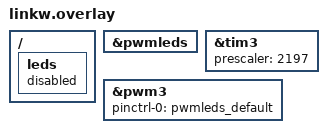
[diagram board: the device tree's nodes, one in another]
/*
 * Copyright (c) 2025 Michael Hope <michaelh@juju.nz>
 *
 * SPDX-License-Identifier: Apache-2.0
 */

/ {
	leds {
		status = "disabled";
	};
};

&pwmleds {
	status = "okay";
};

&tim3 {
	status = "okay";
	/*
	 * The sample runs from 1 Hz to 128 Hz, ceil(144 MHz / 65536 / 1 Hz)
	 * is 2198, and the prescaler property is one less than that.
	 */
	prescaler = <2197>;
};

&pwm3 {
	status = "okay";
	pinctrl-0 = <&pwmleds_default>;
	pinctrl-names = "default";
};
